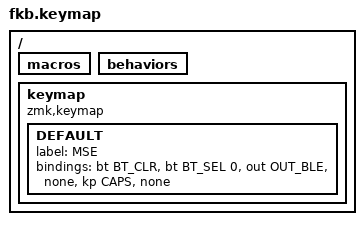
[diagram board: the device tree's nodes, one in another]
#include <behaviors.dtsi>
#include <dt-bindings/zmk/keys.h>
#include <dt-bindings/zmk/bt.h>
#include <dt-bindings/zmk/ext_power.h>
#include <dt-bindings/zmk/outputs.h>

/ {
    macros {
    };

    behaviors {
    };

    keymap {
        compatible = "zmk,keymap";

        DEFAULT {
            label = "MSE";
            bindings = <
&bt BT_CLR  &bt BT_SEL 0  &out OUT_BLE  &none  &kp CAPS  &none
            >;
//trackball-bindings = <&tmv>;
        };
    };
};
